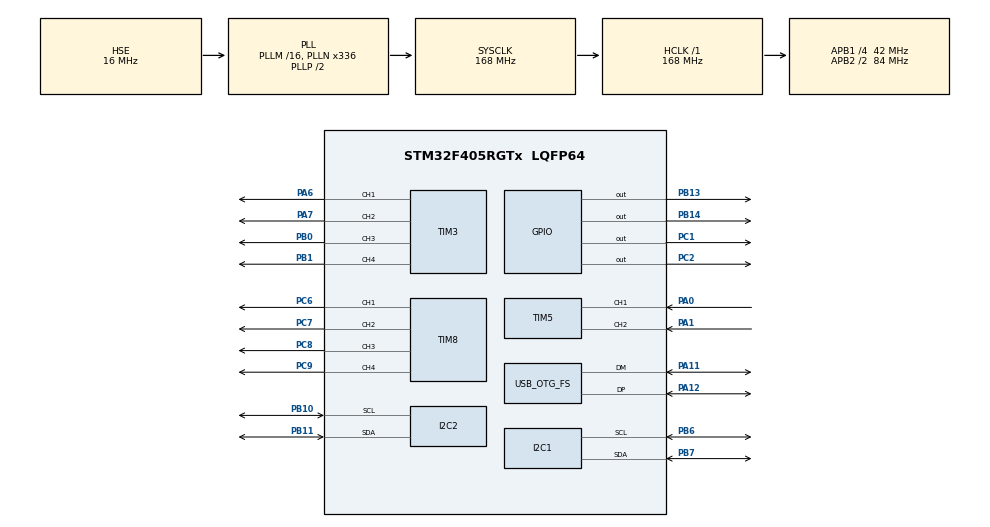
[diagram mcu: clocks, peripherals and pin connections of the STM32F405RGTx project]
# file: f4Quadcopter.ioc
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I2C1.I2C_Mode=I2C_Fast
I2C2.I2C_Mode=I2C_Fast
Mcu.Family=STM32F4
Mcu.Name=STM32F405RGTx
Mcu.Package=LQFP64
NVIC.OTG_FS_IRQn=true\:0\:0\:false\:false\:true\:false\:true
NVIC.PriorityGroup=NVIC_PRIORITYGROUP_4
PA0-WKUP.Signal=S_TIM5_CH1
PA1.Signal=S_TIM5_CH2
PA11.Mode=Device_Only
PA11.Signal=USB_OTG_FS_DM
PA12.Mode=Device_Only
PA12.Signal=USB_OTG_FS_DP
PA6.Signal=S_TIM3_CH1
PA7.Signal=S_TIM3_CH2
PB0.Signal=S_TIM3_CH3
PB1.Signal=S_TIM3_CH4
PB10.Mode=I2C
PB10.Signal=I2C2_SCL
PB11.Mode=I2C
PB11.Signal=I2C2_SDA
PB13.Signal=GPIO_Output
PB14.Signal=GPIO_Output
PB6.Mode=I2C
PB6.Signal=I2C1_SCL
PB7.Mode=I2C
PB7.Signal=I2C1_SDA
PC1.GPIO_ModeDefaultOutputPP=GPIO_MODE_OUTPUT_PP
PC1.GPIO_PuPd=GPIO_NOPULL
PC1.GPIO_Speed=GPIO_SPEED_FREQ_LOW
PC1.PinState=GPIO_PIN_RESET
PC1.Signal=GPIO_Output
PC2.GPIO_ModeDefaultOutputPP=GPIO_MODE_OUTPUT_PP
PC2.GPIO_PuPd=GPIO_NOPULL
PC2.GPIO_Speed=GPIO_SPEED_FREQ_LOW
PC2.PinState=GPIO_PIN_RESET
PC2.Signal=GPIO_Output
PC6.Signal=S_TIM8_CH1
PC7.Signal=S_TIM8_CH2
PC8.Signal=S_TIM8_CH3
PC9.Signal=S_TIM8_CH4
PH0-OSC_IN.Mode=HSE-External-Oscillator
PH0-OSC_IN.Signal=RCC_OSC_IN
PH1-OSC_OUT.Mode=HSE-External-Oscillator
PH1-OSC_OUT.Signal=RCC_OSC_OUT
ProjectManager.HeapSize=0x200
ProjectManager.StackSize=0x400
ProjectManager.TargetToolchain=STM32CubeIDE
RCC.48MHZClocksFreq_Value=48000000
RCC.AHBFreq_Value=168000000
RCC.APB1CLKDivider=RCC_HCLK_DIV4
RCC.APB1Freq_Value=42000000
RCC.APB1TimFreq_Value=84000000
RCC.APB2CLKDivider=RCC_HCLK_DIV2
RCC.APB2Freq_Value=84000000
RCC.APB2TimFreq_Value=168000000
RCC.CortexFreq_Value=168000000
RCC.HCLKFreq_Value=168000000
RCC.HSE_VALUE=16000000
RCC.HSI_VALUE=16000000
RCC.PLLN=336
RCC.PLLQ=7
RCC.RCC_RTC_Clock_Source=RCC_RTCCLKSOURCE_LSI
RCC.RCC_RTC_Clock_SourceVirtual=RCC_RTCCLKSOURCE_LSE
RCC.SYSCLKFreq_VALUE=168000000
RCC.SYSCLKSource=RCC_SYSCLKSOURCE_PLLCLK
RCC.VCOOutputFreq_Value=336000000
SH.S_TIM3_CH1.0=TIM3_CH1,Output Compare1 CH1
SH.S_TIM3_CH2.0=TIM3_CH2,Output Compare2 CH2
SH.S_TIM3_CH3.0=TIM3_CH3,Output Compare3 CH3
SH.S_TIM3_CH4.0=TIM3_CH4,Output Compare4 CH4
SH.S_TIM5_CH1.0=TIM5_CH1,Input_Capture1_from_TI1
SH.S_TIM5_CH2.0=TIM5_CH2,Input_Capture2_from_TI2
SH.S_TIM8_CH1.0=TIM8_CH1,Output Compare1 CH1
SH.S_TIM8_CH2.0=TIM8_CH2,Output Compare2 CH2
SH.S_TIM8_CH3.0=TIM8_CH3,Output Compare3 CH3
SH.S_TIM8_CH4.0=TIM8_CH4,Output Compare4 CH4
TIM3.Channel-Output\ Compare1\ CH1=TIM_CHANNEL_1
TIM3.Channel-Output\ Compare2\ CH2=TIM_CHANNEL_2
TIM3.Channel-Output\ Compare3\ CH3=TIM_CHANNEL_3
TIM3.Channel-Output\ Compare4\ CH4=TIM_CHANNEL_4
TIM5.Channel-Input_Capture1_from_TI1=TIM_CHANNEL_1
TIM5.Channel-Input_Capture2_from_TI2=TIM_CHANNEL_2
TIM8.Channel-Output\ Compare1\ CH1=TIM_CHANNEL_1
TIM8.Channel-Output\ Compare2\ CH2=TIM_CHANNEL_2
TIM8.Channel-Output\ Compare3\ CH3=TIM_CHANNEL_3
TIM8.Channel-Output\ Compare4\ CH4=TIM_CHANNEL_4
USB_DEVICE.CLASS_NAME_FS=CDC
USB_DEVICE.VirtualMode-CDC_FS=Cdc
USB_DEVICE.VirtualModeFS=Cdc_FS
USB_OTG_FS.VirtualMode=Device_Only
VP_RTC_VS_RTC_Activate.Mode=RTC_Enabled
VP_TIM8_VS_ClockSourceINT.Mode=Internal
VP_USB_DEVICE_VS_USB_DEVICE_CDC_FS.Mode=CDC_FS
board=custom

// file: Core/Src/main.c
/* USER CODE BEGIN Header */
/**
  ******************************************************************************
  * @file           : main.c
  * @brief          : Main program body
  ******************************************************************************
  * @attention
  *
  * <h2><center>&copy; Copyright (c) 2020 STMicroelectronics.
  * All rights reserved.</center></h2>
  *
  * This software component is licensed by ST under Ultimate Liberty license
  * SLA0044, the "License"; You may not use this file except in compliance with
  * the License. You may obtain a copy of the License at:
  *                             www.st.com/SLA0044
  *
  ******************************************************************************
  */
/* USER CODE END Header */
#include "main.h"
#include "i2c.h"
#include "rtc.h"
#include "tim.h"
#include "usb_device.h"
#include "gpio.h"

/* USER CODE BEGIN Includes */

#include "usbd_cdc_if.h"
#include "string.h"
#include "mainlogic.h"

/* USER CODE END Includes */

void SystemClock_Config(void);

int main(void)
{

  /* MCU Configuration--------------------------------------------------------*/

  /* Reset of all peripherals, Initializes the Flash interface and the Systick. */
  HAL_Init();

  /* Configure the system clock */
  SystemClock_Config();

  /* Initialize all configured peripherals */
  MX_GPIO_Init();
  MX_I2C1_Init();
  MX_I2C2_Init();
  MX_RTC_Init();
  MX_TIM3_Init();
  MX_TIM5_Init();
  MX_TIM8_Init();
  MX_USB_DEVICE_Init();
  /* USER CODE BEGIN 2 */

  main_setup();

  /* USER CODE END 2 */

  /* Infinite loop */
  /* USER CODE BEGIN WHILE */
  while (1)
  {
	  main_loop();

    /* USER CODE END WHILE */

  }
}

void SystemClock_Config(void)
{
  RCC_OscInitTypeDef RCC_OscInitStruct = {0};
  RCC_ClkInitTypeDef RCC_ClkInitStruct = {0};
  RCC_PeriphCLKInitTypeDef PeriphClkInitStruct = {0};

  /** Configure the main internal regulator output voltage
  */
  __HAL_RCC_PWR_CLK_ENABLE();
  __HAL_PWR_VOLTAGESCALING_CONFIG(PWR_REGULATOR_VOLTAGE_SCALE1);
  /** Initializes the RCC Oscillators according to the specified parameters
  * in the RCC_OscInitTypeDef structure.
  */
  RCC_OscInitStruct.OscillatorType = RCC_OSCILLATORTYPE_LSI|RCC_OSCILLATORTYPE_HSE;
  RCC_OscInitStruct.HSEState = RCC_HSE_ON;
  RCC_OscInitStruct.LSIState = RCC_LSI_ON;
  RCC_OscInitStruct.PLL.PLLState = RCC_PLL_ON;
  RCC_OscInitStruct.PLL.PLLSource = RCC_PLLSOURCE_HSE;
  RCC_OscInitStruct.PLL.PLLM = 16;
  RCC_OscInitStruct.PLL.PLLN = 336;
  RCC_OscInitStruct.PLL.PLLP = RCC_PLLP_DIV2;
  RCC_OscInitStruct.PLL.PLLQ = 7;
  if (HAL_RCC_OscConfig(&RCC_OscInitStruct) != HAL_OK)
  {
    Error_Handler();
  }
  /** Initializes the CPU, AHB and APB buses clocks
  */
  RCC_ClkInitStruct.ClockType = RCC_CLOCKTYPE_HCLK|RCC_CLOCKTYPE_SYSCLK
                              |RCC_CLOCKTYPE_PCLK1|RCC_CLOCKTYPE_PCLK2;
  RCC_ClkInitStruct.SYSCLKSource = RCC_SYSCLKSOURCE_PLLCLK;
  RCC_ClkInitStruct.AHBCLKDivider = RCC_SYSCLK_DIV1;
  RCC_ClkInitStruct.APB1CLKDivider = RCC_HCLK_DIV4;
  RCC_ClkInitStruct.APB2CLKDivider = RCC_HCLK_DIV2;

  if (HAL_RCC_ClockConfig(&RCC_ClkInitStruct, FLASH_LATENCY_5) != HAL_OK)
  {
    Error_Handler();
  }
  PeriphClkInitStruct.PeriphClockSelection = RCC_PERIPHCLK_RTC;
  PeriphClkInitStruct.RTCClockSelection = RCC_RTCCLKSOURCE_LSI;
  if (HAL_RCCEx_PeriphCLKConfig(&PeriphClkInitStruct) != HAL_OK)
  {
    Error_Handler();
  }
}

void Error_Handler(void)
{
}

/************************ (C) COPYRIGHT STMicroelectronics *****END OF FILE****/
